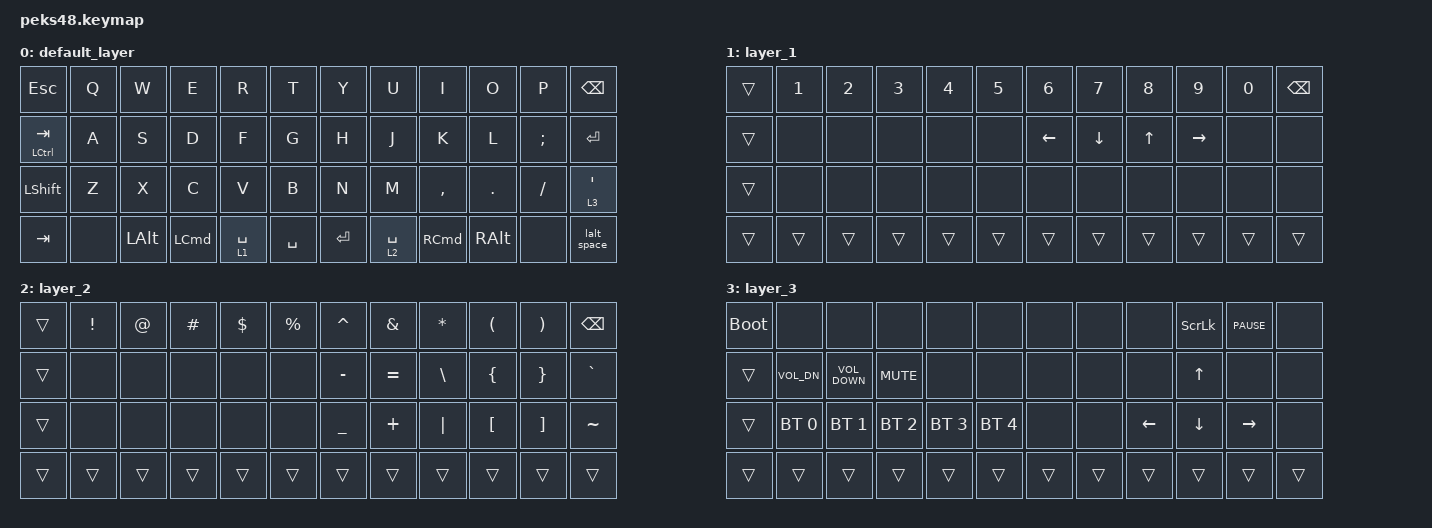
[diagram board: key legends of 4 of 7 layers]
#include <input/processors.dtsi>
#include <dt-bindings/zmk/input_transform.h>
#include <zephyr/dt-bindings/input/input-event-codes.h>
#include <behaviors.dtsi>
#include <dt-bindings/zmk/bt.h>
#include <dt-bindings/zmk/keys.h>
#include <dt-bindings/zmk/pointing.h>

// Conversion definition for using Japanese keyboard with OS settings

#define JP_DQUOTE       AT                // "
#define JP_AMPERSAND    CARET             // &
#define JP_QUOTE        AMPERSAND         // '
#define JP_EQUAL        UNDER             // =
#define JP_CARET        EQUAL             // ^
#define JP_YEN          0x89              // ¥
#define JP_PLUS         COLON             // +
#define JP_TILDE        PLUS              // ~
#define JP_PIPE         LS(0x89)          // |
#define JP_AT           LEFT_BRACKET      // @
#define JP_COLON        SINGLE_QUOTE      // :
#define JP_ASTERISK     DOUBLE_QUOTES     // *
#define JP_BACKQUOTE    LEFT_BRACE        // `
#define JP_UNDERSCORE   LS(0x87)          // _
#define JP_LBRACKET     RIGHT_BRACKET     // [
#define JP_RBRACKET     BACKSLASH         // ]
#define JP_LPAREN       ASTERISK          // (
#define JP_RPAREN       LEFT_PARENTHESIS  // )
#define JP_LBRACE       RIGHT_BRACE       // {
#define JP_RBRACE       PIPE              // }
#define JP_KANA         LANGUAGE_1        // かな
#define JP_EISU         LANGUAGE_2        // 英数
#define JP_HANZEN       GRAVE             // 半角/全角

&mt {
    flavor = "balanced";
    quick-tap-ms = <0>;
};

/ {
    macros {
        lalt_space: lalt_space {
            compatible = "zmk,behavior-macro";
            #binding-cells = <0>;
            bindings =
                <&macro_press>,
                <&kp LALT>,
                <&macro_tap>,
                <&kp SPACE>,
                <&macro_release>,
                <&kp LALT>;

            label = "LALT_SPACE";
        };
    };

    keymap {
        compatible = "zmk,keymap";

        default_layer {
            bindings = <
&kp ESC        &kp Q  &kp W     &kp E     &kp R        &kp T        &kp Y      &kp U        &kp I      &kp O     &kp P          &kp BACKSPACE
&mt LCTRL TAB  &kp A  &kp S     &kp D     &kp F        &kp G        &kp H      &kp J        &kp K      &kp L     &kp SEMICOLON  &kp ENTER
&kp LSHIFT     &kp Z  &kp X     &kp C     &kp V        &kp B        &kp N      &kp M        &kp COMMA  &kp DOT   &kp SLASH      &lt 3 SQT
&kp TAB        &none  &kp LALT  &kp LCMD  &lt 1 SPACE  &kp SPACE    &kp ENTER  &lt 2 SPACE  &kp RCMD   &kp RALT  &none          &lalt_space
            >;
        };

        layer_1 {
            bindings = <
&trans  &kp NUMBER_1  &kp NUMBER_2  &kp NUMBER_3  &kp NUMBER_4  &kp NUMBER_5    &kp NUMBER_6  &kp NUMBER_7  &kp NUMBER_8  &kp NUMBER_9  &kp NUMBER_0  &kp BACKSPACE
&trans  &none         &none         &none         &none         &none           &kp LEFT      &kp DOWN      &kp UP_ARROW  &kp RIGHT     &none         &none
&trans  &none         &none         &none         &none         &none           &none         &none         &none         &none         &none         &none
&trans  &trans        &trans        &trans        &trans        &trans          &trans        &trans        &trans        &trans        &trans        &trans
            >;
        };

        layer_2 {
            bindings = <
&trans  &kp EXCLAMATION  &kp AT  &kp POUND  &kp DOLLAR  &kp PERCENT    &kp CARET       &kp AMPERSAND  &kp ASTERISK   &kp LEFT_PARENTHESIS  &kp RIGHT_PARENTHESIS  &kp BACKSPACE
&trans  &none            &none   &none      &none       &none          &kp MINUS       &kp EQUAL      &kp BACKSLASH  &kp LEFT_BRACE        &kp RIGHT_BRACE        &kp GRAVE
&trans  &none            &none   &none      &none       &none          &kp UNDERSCORE  &kp PLUS       &kp PIPE       &kp LEFT_BRACKET      &kp RIGHT_BRACKET      &kp TILDE
&trans  &trans           &trans  &trans     &trans      &trans         &trans          &trans         &trans         &trans                &trans                 &trans
            >;
        };

        layer_3 {
            bindings = <
&bootloader  &none         &none              &none         &none         &none           &none   &none   &none           &kp SCROLLLOCK  &kp C_PAUSE      &none
&trans       &kp C_VOL_DN  &kp C_VOLUME_DOWN  &kp C_MUTE    &none         &none           &none   &none   &none           &kp UP_ARROW    &none            &none
&trans       &bt BT_SEL 0  &bt BT_SEL 1       &bt BT_SEL 2  &bt BT_SEL 3  &bt BT_SEL 4    &none   &none   &kp LEFT_ARROW  &kp DOWN_ARROW  &kp RIGHT_ARROW  &none
&trans       &trans        &trans             &trans        &trans        &trans          &trans  &trans  &trans          &trans          &trans           &trans
            >;
        };

        layer_4 {
            bindings = <
&trans  &trans  &trans  &trans  &trans  &trans    &trans       &bt BT_SEL 0  &bt BT_SEL 1  &bt BT_SEL 2  &bt BT_SEL 3  &bt BT_SEL 4
&trans  &trans  &trans  &trans  &trans  &trans    &trans       &tog 6        &trans        &trans        &trans        &bt BT_CLR
&trans  &trans  &trans  &trans  &trans  &trans    &bootloader  &trans        &trans        &trans        &trans        &bt BT_CLR_ALL
&trans  &trans  &trans  &trans
            >;
        };

        layer_5 {
            bindings = <
&trans  &trans  &trans    &trans    &trans    &trans    &trans  &trans    &trans    &trans    &trans  &trans
&trans  &trans  &mkp MB3  &mkp MB2  &mkp MB1  &trans    &trans  &mkp MB1  &mkp MB2  &mkp MB3  &trans  &trans
&trans  &trans  &trans    &trans    &trans    &trans    &trans  &trans    &trans    &trans    &trans  &trans
&trans  &trans  &trans    &trans
            >;
        };

        layer_6 {
            bindings = <
&trans  &trans  &trans  &trans  &trans  &trans    &trans  &trans  &trans    &trans    &trans    &trans
&trans  &trans  &trans  &trans  &trans  &trans    &trans  &trans  &mkp MB1  &mkp MB3  &mkp MB2  &trans
&trans  &trans  &trans  &trans  &trans  &trans    &trans  &trans  &trans    &trans    &trans    &trans
&trans  &trans  &trans  &trans
            >;
        };
    };
};
